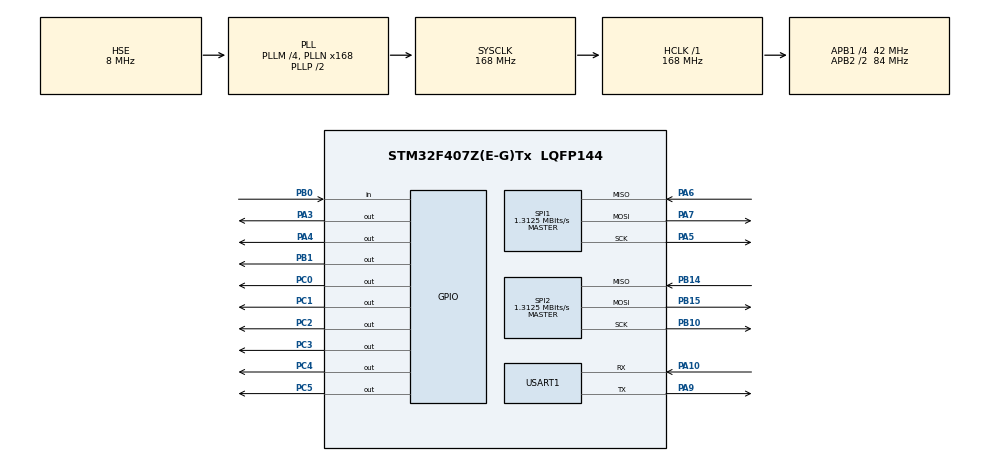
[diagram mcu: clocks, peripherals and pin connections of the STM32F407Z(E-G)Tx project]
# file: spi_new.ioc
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Mcu.Family=STM32F4
Mcu.Name=STM32F407Z(E-G)Tx
Mcu.Package=LQFP144
NVIC.PriorityGroup=NVIC_PRIORITYGROUP_4
PA10.Mode=Asynchronous
PA10.Signal=USART1_RX
PA13.Mode=Serial_Wire
PA13.Signal=SYS_JTMS-SWDIO
PA14.Mode=Serial_Wire
PA14.Signal=SYS_JTCK-SWCLK
PA3.Signal=GPIO_Output
PA4.GPIO_ModeDefaultOutputPP=GPIO_MODE_OUTPUT_PP
PA4.GPIO_Speed=GPIO_SPEED_FREQ_VERY_HIGH
PA4.PinState=GPIO_PIN_SET
PA4.Signal=GPIO_Output
PA5.Mode=Full_Duplex_Master
PA5.Signal=SPI1_SCK
PA6.Mode=Full_Duplex_Master
PA6.Signal=SPI1_MISO
PA7.Mode=Full_Duplex_Master
PA7.Signal=SPI1_MOSI
PA9.Mode=Asynchronous
PA9.Signal=USART1_TX
PB0.GPIO_PuPd=GPIO_PULLUP
PB0.Signal=GPIO_Input
PB1.GPIO_ModeDefaultOutputPP=GPIO_MODE_OUTPUT_PP
PB1.GPIO_PuPd=GPIO_PULLUP
PB1.GPIO_Speed=GPIO_SPEED_FREQ_HIGH
PB1.PinState=GPIO_PIN_SET
PB1.Signal=GPIO_Output
PB10.Mode=Full_Duplex_Master
PB10.Signal=SPI2_SCK
PB14.Mode=Full_Duplex_Master
PB14.Signal=SPI2_MISO
PB15.Mode=Full_Duplex_Master
PB15.Signal=SPI2_MOSI
PC0.GPIO_ModeDefaultOutputPP=GPIO_MODE_OUTPUT_PP
PC0.GPIO_PuPd=GPIO_NOPULL
PC0.GPIO_Speed=GPIO_SPEED_FREQ_HIGH
PC0.PinState=GPIO_PIN_SET
PC0.Signal=GPIO_Output
PC1.GPIO_ModeDefaultOutputPP=GPIO_MODE_OUTPUT_PP
PC1.GPIO_PuPd=GPIO_PULLUP
PC1.GPIO_Speed=GPIO_SPEED_FREQ_HIGH
PC1.PinState=GPIO_PIN_SET
PC1.Signal=GPIO_Output
PC2.GPIO_ModeDefaultOutputPP=GPIO_MODE_OUTPUT_PP
PC2.GPIO_PuPd=GPIO_PULLUP
PC2.GPIO_Speed=GPIO_SPEED_FREQ_HIGH
PC2.PinState=GPIO_PIN_SET
PC2.Signal=GPIO_Output
PC3.GPIO_ModeDefaultOutputPP=GPIO_MODE_OUTPUT_PP
PC3.GPIO_PuPd=GPIO_PULLUP
PC3.GPIO_Speed=GPIO_SPEED_FREQ_HIGH
PC3.PinState=GPIO_PIN_SET
PC3.Signal=GPIO_Output
PC4.GPIO_ModeDefaultOutputPP=GPIO_MODE_OUTPUT_PP
PC4.GPIO_PuPd=GPIO_PULLUP
PC4.GPIO_Speed=GPIO_SPEED_FREQ_HIGH
PC4.PinState=GPIO_PIN_SET
PC4.Signal=GPIO_Output
PC5.GPIO_ModeDefaultOutputPP=GPIO_MODE_OUTPUT_PP
PC5.GPIO_PuPd=GPIO_PULLUP
PC5.GPIO_Speed=GPIO_SPEED_FREQ_HIGH
PC5.PinState=GPIO_PIN_SET
PC5.Signal=GPIO_Output
PH0-OSC_IN.Mode=HSE-External-Oscillator
PH0-OSC_IN.Signal=RCC_OSC_IN
PH1-OSC_OUT.Mode=HSE-External-Oscillator
PH1-OSC_OUT.Signal=RCC_OSC_OUT
ProjectManager.HeapSize=0x800
ProjectManager.StackSize=0x800
ProjectManager.TargetToolchain=MDK-ARM V5.32
RCC.48MHZClocksFreq_Value=84000000
RCC.AHBFreq_Value=168000000
RCC.APB1CLKDivider=RCC_HCLK_DIV4
RCC.APB1Freq_Value=42000000
RCC.APB1TimFreq_Value=84000000
RCC.APB2CLKDivider=RCC_HCLK_DIV2
RCC.APB2Freq_Value=84000000
RCC.APB2TimFreq_Value=168000000
RCC.CortexFreq_Value=168000000
RCC.HCLKFreq_Value=168000000
RCC.HSE_VALUE=8000000
RCC.HSI_VALUE=16000000
RCC.LSE_VALUE=32768
RCC.PLLM=4
RCC.PLLN=168
RCC.PLLSourceVirtual=RCC_PLLSOURCE_HSE
RCC.SYSCLKFreq_VALUE=168000000
RCC.SYSCLKSource=RCC_SYSCLKSOURCE_PLLCLK
RCC.VCOOutputFreq_Value=336000000
SPI1.BaudRatePrescaler=SPI_BAUDRATEPRESCALER_64
SPI1.CalculateBaudRate=1.3125 MBits/s
SPI1.DataSize=SPI_DATASIZE_16BIT
SPI1.Direction=SPI_DIRECTION_2LINES
SPI1.Mode=SPI_MODE_MASTER
SPI1.VirtualType=VM_MASTER
SPI2.BaudRatePrescaler=SPI_BAUDRATEPRESCALER_32
SPI2.CalculateBaudRate=1.3125 MBits/s
SPI2.DataSize=SPI_DATASIZE_16BIT
SPI2.Direction=SPI_DIRECTION_2LINES
SPI2.Mode=SPI_MODE_MASTER
SPI2.VirtualType=VM_MASTER
USART1.VirtualMode=VM_ASYNC
board=custom

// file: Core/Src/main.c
/* USER CODE BEGIN Header */
/**
  ******************************************************************************
  * @file           : main.c
  * @brief          : Main program body
  ******************************************************************************
  * @attention
  *
  * Copyright (c) 2025 STMicroelectronics.
  * All rights reserved.
  *
  * This software is licensed under terms that can be found in the LICENSE file
  * in the root directory of this software component.
  * If no LICENSE file comes with this software, it is provided AS-IS.
  *
  ******************************************************************************
  */
/* USER CODE END Header */
#include "main.h"
#include "spi.h"
#include "usart.h"
#include "gpio.h"

/* USER CODE BEGIN Includes */
#include "bsp_system.h"
/* USER CODE END Includes */

void SystemClock_Config(void);
/* USER CODE BEGIN PFP */
/* 保存扫频得到的复数频率响应 H(jw)，供后续拟合和系数计算使用。 */
complex sample_array[SAMPLE_NUM];
/* USER CODE END PFP */

int main(void)
{

  /* MCU Configuration--------------------------------------------------------*/

  /* Reset of all peripherals, Initializes the Flash interface and the Systick. */
  HAL_Init();

  /* Configure the system clock */
  SystemClock_Config();

  /* Initialize all configured peripherals */
  MX_GPIO_Init();
  MX_SPI1_Init();
  MX_USART1_UART_Init();
  MX_SPI2_Init();
  /* USER CODE BEGIN 2 */
  /*
   * 保留当前工程的板级引脚和外设配置，
   * 复用 G_Project-32 的自动滤波器设计流程。
   */
  AD9954_Init();

//	AD9954_SetFre(200);
//  AD9954_Voltage_Control(16383);

  analog_coef ac;
  digital_coef dc;

//AD9954_SetFre(200);
//HAL_Delay(1000);
//AD9954_SetFre(400);

printf("start\n");
//  /* 步骤 1：扫频，获取 200 Hz 到 50 kHz 的复数频率响应。 */
 freq_scan(sample_array);

  /* 步骤 2：根据频率响应构造最小二乘方程所需的系数。 */
  coef_calc(sample_array);

  /* 步骤 3：求解 5x5 线性方程组，得到模拟二阶滤波器参数。 */
  ac = matrix_calc();

  /* 步骤 4：通过双线性变换得到数字滤波器系数并量化。 */
  dc = bilinear_transform_quant(&ac);

  /* 步骤 5：根据低频/高频增益特征识别滤波器类型。 */
  get_filter_type(&ac);

  /* 步骤 6：将量化后的数字滤波器系数写入外部逻辑。 */
  coef_lode(&dc);
  /* USER CODE END 2 */

  /* Infinite loop */
  while (1)
  {

    /* USER CODE BEGIN 3 */
    /* 主流程上电只执行一次，随后停在此处便于串口观察与联调。 */
  }
  /* USER CODE END 3 */
}

void SystemClock_Config(void)
{
  RCC_OscInitTypeDef RCC_OscInitStruct = {0};
  RCC_ClkInitTypeDef RCC_ClkInitStruct = {0};

  /** Configure the main internal regulator output voltage
  */
  __HAL_RCC_PWR_CLK_ENABLE();
  __HAL_PWR_VOLTAGESCALING_CONFIG(PWR_REGULATOR_VOLTAGE_SCALE1);

  /** Initializes the RCC Oscillators according to the specified parameters
  * in the RCC_OscInitTypeDef structure.
  */
  RCC_OscInitStruct.OscillatorType = RCC_OSCILLATORTYPE_HSE;
  RCC_OscInitStruct.HSEState = RCC_HSE_ON;
  RCC_OscInitStruct.PLL.PLLState = RCC_PLL_ON;
  RCC_OscInitStruct.PLL.PLLSource = RCC_PLLSOURCE_HSE;
  RCC_OscInitStruct.PLL.PLLM = 4;
  RCC_OscInitStruct.PLL.PLLN = 168;
  RCC_OscInitStruct.PLL.PLLP = RCC_PLLP_DIV2;
  RCC_OscInitStruct.PLL.PLLQ = 4;
  if (HAL_RCC_OscConfig(&RCC_OscInitStruct) != HAL_OK)
  {
    Error_Handler();
  }

  /** Initializes the CPU, AHB and APB buses clocks
  */
  RCC_ClkInitStruct.ClockType = RCC_CLOCKTYPE_HCLK|RCC_CLOCKTYPE_SYSCLK
                              |RCC_CLOCKTYPE_PCLK1|RCC_CLOCKTYPE_PCLK2;
  RCC_ClkInitStruct.SYSCLKSource = RCC_SYSCLKSOURCE_PLLCLK;
  RCC_ClkInitStruct.AHBCLKDivider = RCC_SYSCLK_DIV1;
  RCC_ClkInitStruct.APB1CLKDivider = RCC_HCLK_DIV4;
  RCC_ClkInitStruct.APB2CLKDivider = RCC_HCLK_DIV2;

  if (HAL_RCC_ClockConfig(&RCC_ClkInitStruct, FLASH_LATENCY_5) != HAL_OK)
  {
    Error_Handler();
  }
}

void Error_Handler(void)
{
  __disable_irq();
  while (1)
  {
  }
}
